# MIMXRT685S_cm33 register map
Vendor: nxp.com; File version: 1.0
CPU: CM33 r2p0, little endian, MPU, FPU, VTOR, 3 interrupt priority bits
Registers are 32-bit, read-write, reset 0x0 unless marked. A register's access mark holds for its fields unless they carry their own. Offsets are from the block's base; [hi:lo] are bit positions; {n}, {i} and the like mark numbered series.

## MUA — LPC-Next0 MUA
Base 0x40110000
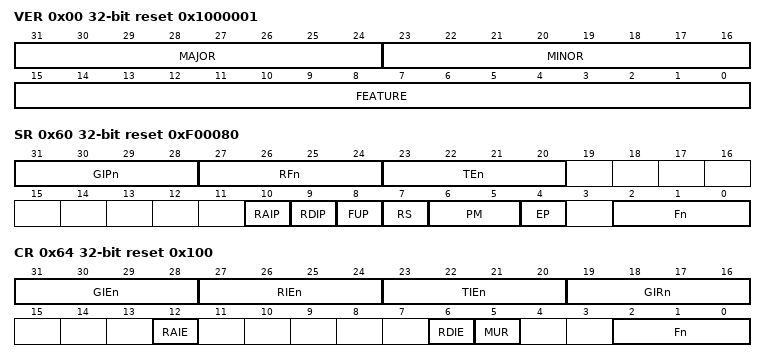
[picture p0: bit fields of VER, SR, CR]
0x00 VER ro reset 0x1000001 — Version ID Register
  [31:24] MAJOR — Major Version Number
  [23:16] MINOR — Minor Version Number
  [15:0] FEATURE — Feature Specification Number
    0=Standard features implemented; 1=RAIP and RAIE register bits implemented on MUA side; 2=MUA and MUB implemented with the same function. some bits in CR register are moved to CCR register.; 4=some sync logic are deleted for synchronized MUA and MUB. RAIP and RDIP monitor Core reset instead of MU reset. Add HRIP and MURIP and their interrupt enable bits on both sides. Delete RS bit. Add COO mode in PM state.
0x04 PAR ro — Use Parameter register to determine the parameter settings of MUA.
  [31:0] PARAMETER
{0x20+4i} TR[{i}] (i=0..3) — Transmit Register
  [31:0] DATA
{0x40+4i} RR[{i}] (i=0..3) — Receive Register.
  [31:0] DATA
0x60 SR reset 0xF00080 — Status Register
  [31:28] GIPn
    0=MUA general purpose interrupt n is not pending. (default); 1=MUA general purpose interrupt n is pending
  [27:24] RFn ro
    0=MUA RRn register is not full (default); 1=MUA RRn register has received data from MUB TRn register and is ready to be read by the MUA
  [23:20] TEn ro
    0=MUA TRn register is not empty; 1=MUA TRn register is empty (default)
  [10] RAIP
    0=Processor B-side did not enter reset; 1=Processor B-side entered reset
  [9] RDIP — BRDIP
    0=Processor B-side did not exit reset; 1=Processor B-side exited from reset
  [8] FUP ro
    0=No flags updated, initiated by the MUA, in progress (default); 1=MUA initiated flags update, processing
  [7] RS ro
    0=The MUB side of the MU is not in reset; 1=The MUB side of the MU is in reset
  [6:5] PM ro
    0=RUN (The MUB processor is in Run Mode.); 1=WAIT (The MUB processor is in WAIT Mode.)
  [4] EP ro
    0=The MUA side event is not pending (default); 1=The MUA side event is pending
  [2:0] Fn ro
    0=Fn bit in the CR register is written 0 (default); 1=Fn bit in the CR register is written 1
0x64 CR reset 0x100 — Control Register
  [31:28] GIEn
    0=Disables MUA General Interrupt n. (default); 1=Enables MUA General Interrupt n
  [27:24] RIEn
    0=Disables MUA Receive Interrupt n. (default); 1=Enables MUA Receive Interrupt n
  [23:20] TIEn
    0=Disables MUA Transmit Interrupt n. (default); 1=Enables MUA Transmit Interrupt n
  [19:16] GIRn
    0=MUA General Interrupt n is not requested to the MUB (default); 1=MUA General Interrupt n is requested to the MUB
  [12] RAIE
    0=Disables Processor A General Purpose Interrupt 3 request due to Processor B reset assertion; 1=Enables Processor A General Purpose Interrupt 3 request due to Processor B reset assertion
  [6] RDIE — BRDIE
    0=Disables Processor A General Purpose Interrupt 3 request due to Processor B reset de-assertion; 1=Enables Processor A General Purpose Interrupt 3 request due to Processor B reset de-assertion
  [5] MUR
    0=N/A. Self clearing bit (default).; 1=Asserts the MU reset
  [2:0] Fn
    0=Clears the Fn bit in the SR register; 1=Sets the Fn bit in the SR register

## SEMA42 — LPC-Next0 SEMA
Base 0x40112000
0x00 GATE{x} (x=3,2,1,0,7,6,5,4,11,10,9,8,15,14,13,12; step 0x1) 8-bit — Semphores2 Gate n
  [3:0] GTFSM — ate Finite State Machine. The hardware gate is maintained in a 16-state implementation
    0=The gate is unlocked (free); 1=The gate has been locked by processor 0; 2=The gate has been locked by processor 1
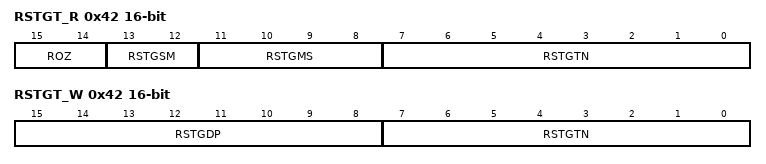
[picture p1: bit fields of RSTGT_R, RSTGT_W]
0x42 RSTGT_R 16-bit ro (RSTGT view) — Reset Gate Read
  [15:14] ROZ
  [13:12] RSTGSM
    0=Idle, waiting for the first data pattern write; 1=Waiting for the second data pattern write; 2=The 2-write sequence has completed. Generate the specified gate reset(s). After the reset is performed, this machine returns to the idle (waiting for first data pattern write) state. The "01" state persists for only one clock cycle. Software cannot observe this state.; 3=This state encoding is never used and therefore reserved
  [11:8] RSTGMS
  [7:0] RSTGTN
0x42 RSTGT_W 16-bit wo reset not defined (RSTGT view) — Reset Gate Write
  [15:8] RSTGDP, [7:0] RSTGTN
